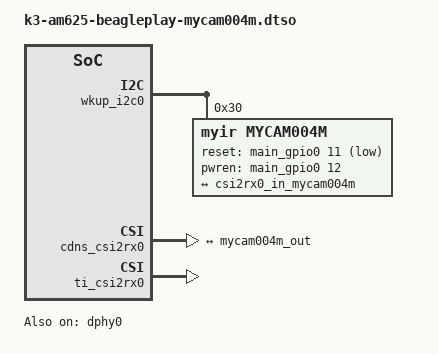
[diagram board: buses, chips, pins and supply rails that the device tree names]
// SPDX-License-Identifier: GPL-2.0-only OR MIT
/*
 * MYIR MY-CAM004M - quad-AHD-camera-input to 4-lane MIPI CSI-2 decoder
 *
 * Connects MY-CAM004M to BeaglePlay (AM625) via J17. Modeled after the
 * upstream single-camera reference overlays for this connector
 * (k3-am625-beagleplay-csi2-ov5640.dtso /
 * k3-am625-beagleplay-csi2-tevi-ov5640.dtso), extended to 4 lanes and
 * carrying this driver's I2C GPIO reset/enable properties instead of a
 * gpio-hog (this decoder's own driver manages those lines, unlike the
 * ov5640 examples which tie a pin high externally via hog because the
 * ov5640 driver itself doesn't touch it).
 *
 * I2C address, GPIO polarity, and lane count/data-lanes below are
 * confirmed against the MY-CAM004M schematic and the Nextchip N4
 * datasheet (MY-CAM004M's decoder chip) -- see mycam004m-regs.h for the
 * full citation trail. link-frequencies remains the one value NOT
 * sourced from N4's own datasheet -- see its own comment below. None of
 * this has been tested against real hardware.
 */

/dts-v1/;
/plugin/;

#include <dt-bindings/gpio/gpio.h>

&wkup_i2c0 {
	#address-cells = <1>;
	#size-cells = <0>;
	status = "okay";

	mycam004m: camera@30 {
		compatible = "myir,mycam004m";

		/*
		 * Confirmed against the MY-CAM004M schematic: it labels
		 * the board's I2C address directly ("I2C add 0x61", the
		 * 8-bit read address for SA0=SA1=Low), which is 7-bit
		 * 0x30 -- also exactly matching N4's own datasheet formula
		 * (address = 0b0110000 | (SA1<<1) | SA0, i.e. 0x30-0x33
		 * across the 4 SA0/SA1 strap combinations). Still worth a
		 * sanity check against a populated board if anything seems
		 * off:
		 *   i2cdetect -y $(basename $(readlink -f \
		 *     /sys/bus/i2c/devices/i2c-4)) 2>/dev/null || \
		 *     i2cdetect -y 4
		 * (wkup_i2c0 is exposed as i2c4 on BeaglePlay -- see
		 * k3-am625-beagleplay.dts's aliases node.)
		 */
		reg = <0x30>;

		/*
		 * BeaglePlay's J17 camera connector only routes two
		 * general-purpose GPIOs from the SoC (main_gpio0 pins
		 * 11/12, labeled CSI2_CAMERA_GPIO1/2 in
		 * k3-am625-beagleplay.dts's gpio-line-names) -- not
		 * three. Per project decision: RESET_N and PWREN use
		 * those two; PWRDN is left unmanaged here (assumed
		 * either tied active on the MY-CAM004M board itself, or
		 * unused). mycam004m.c still requests a "pwrdn-gpios"
		 * property as fully optional, so a future carrier board
		 * that does wire a third GPIO can add it here with no
		 * driver change.
		 *
		 * Confirmed against the MY-CAM004M schematic: RESET_N
		 * wires straight through (no inverter) to N4's RSTB pin,
		 * documented "System Reset (Active Low)" -- GPIO_ACTIVE_LOW
		 * is correct. PWREN wires straight through (0R) to the EN
		 * pin of the board's SGM2028-ADJ LDO, a standard
		 * active-high enable -- GPIO_ACTIVE_HIGH is correct.
		 */
		reset-gpios = <&main_gpio0 11 GPIO_ACTIVE_LOW>;
		pwren-gpios = <&main_gpio0 12 GPIO_ACTIVE_HIGH>;

		port {
			mycam004m_out: endpoint {
				remote-endpoint = <&csi2rx0_in_mycam004m>;
				clock-lanes = <0>;
				data-lanes = <1 2 3 4>;

				/*
				 * ~1242 Mbps/lane -- N4's/NVP6324's fastest
				 * of four discrete MIPI PHY clock steps
				 * (378/594/756/1242 MHz), comfortably above
				 * this board's throughput floor:
				 *
				 *   min bps/lane = (1920*1080*30*16) / 4
				 *                =~ 249 Mbps
				 *
				 * *** NOT a MY-CAM004M / N4 datasheet value
				 * *** -- N4's own datasheet leaves its
				 * MIPI HS/LP transmitter AC timing table
				 * entirely "TBD" (preliminary Rev 0.0).
				 * Sourced instead from the exact register
				 * recipe mycam004m_csi_output_regs[] in
				 * mycam004m-regs.h writes to select this
				 * PLL step, cross-confirmed almost
				 * byte-for-byte between two independent
				 * register-compatible sibling-chip
				 * (NVP6324) drivers -- see that file for
				 * the full citation and the one differing
				 * byte pair. mycam004m.c has no hardcoded
				 * fallback, so revising this remains a
				 * DT-only change if real hardware disagrees.
				 */
				link-frequencies = /bits/ 64 <1242000000>;
			};
		};
	};
};

&cdns_csi2rx0 {
	ports {
		#address-cells = <1>;
		#size-cells = <0>;

		csi0_port0: port@0 {
			reg = <0>;
			status = "okay";

			csi2rx0_in_mycam004m: endpoint {
				remote-endpoint = <&mycam004m_out>;
				bus-type = <4>; /* CSI2 DPHY */
				clock-lanes = <0>;
				data-lanes = <1 2 3 4>;
			};
		};
	};
};

&dphy0 {
	status = "okay";
};

&ti_csi2rx0 {
	status = "okay";
};
